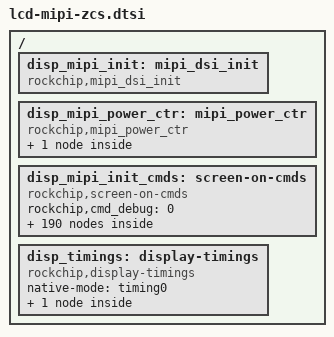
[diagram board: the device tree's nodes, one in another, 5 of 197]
/*
 * Copyright (C) 2014 ROCKCHIP, Inc.
 * Licensed under GPLv2 or later.
 * arch/arm/boot/dts/lcd-b080xan03.0-mipi.dtsi
 * author: chenyf@rock-chips.com
 * create date: 2014-09-11
 * lcd model: b080xan03.0
 * resolution: 768 X 1024
 * mipi channel: single
 */
//#include "include/dt-bindings/rkmipi/mipi_dsi.h"
#define HSDT                    0x00
#define LPDT                    0x01
/ {
		/* about mipi */
		disp_mipi_init: mipi_dsi_init{
					compatible = "rockchip,mipi_dsi_init";
					rockchip,screen_init	= <1>;
					rockchip,dsi_lane		= <4>;
					rockchip,dsi_hs_clk		= <480>;
					rockchip,mipi_dsi_num	= <1>;
		};
		disp_mipi_power_ctr: mipi_power_ctr {
					compatible = "rockchip,mipi_power_ctr";
					mipi_lcd_rst:mipi_lcd_rst{
							compatible = "rockchip,lcd_rst";
							rockchip,gpios = <&gpio0 GPIO_D0 GPIO_ACTIVE_HIGH>;
							rockchip,delay = <300>;
					};
					/*
					mipi_lcd_en:mipi_lcd_en {
							compatible = "rockchip,lcd_en";
							rockchip,gpios = <&gpio1 GPIO_B4 GPIO_ACTIVE_HIGH>;
							rockchip,delay = <100>;
					};*/
		};

disp_mipi_init_cmds: screen-on-cmds {
					compatible = "rockchip,screen-on-cmds";
					rockchip,cmd_debug = <0>;
					
					rockchip,on-cmds1 {
							compatible = "rockchip,on-cmds";
							rockchip,cmd_type = <LPDT>;
							rockchip,dsi_id = <0>;
							rockchip,cmd = <0x39 0xFF 0x98 0x81 0x03>;
							rockchip,cmd_delay = <0>;
					};
					
					rockchip,on-cmds2 {
							compatible = "rockchip,on-cmds";
							rockchip,cmd_type = <LPDT>;
							rockchip,dsi_id = <0>;
							rockchip,cmd = <0x15 0x01 0x00>;
							rockchip,cmd_delay = <0>;
					};
/*--------------------------------------------------------------------------------------------*/				
					rockchip,on-cmds3 {
							compatible = "rockchip,on-cmds";
							rockchip,cmd_type = <LPDT>;
							rockchip,dsi_id = <0>;
							rockchip,cmd = <0x15 0x02 0x00>;
							rockchip,cmd_delay = <0>;
					};
					rockchip,on-cmds4 {
							compatible = "rockchip,on-cmds";
							rockchip,cmd_type = <LPDT>;
							rockchip,dsi_id = <0>;
							rockchip,cmd = <0x15 0x03 0x53>;
							rockchip,cmd_delay = <0>;
					};
					rockchip,on-cmds5 {
							compatible = "rockchip,on-cmds";
							rockchip,cmd_type = <LPDT>;
							rockchip,dsi_id = <0>;
							rockchip,cmd = <0x15 0x04 0x14>;
							rockchip,cmd_delay = <0>;
					};
					rockchip,on-cmds6 {
							compatible = "rockchip,on-cmds";
							rockchip,cmd_type = <LPDT>;
							rockchip,dsi_id = <0>;
							rockchip,cmd = <0x15 0x05 0x00>;
							rockchip,cmd_delay = <0>;
					};
					rockchip,on-cmds7 {
							compatible = "rockchip,on-cmds";
							rockchip,cmd_type = <LPDT>;
							rockchip,dsi_id = <0>;
							rockchip,cmd = <0x15 0x06 0x06>;
							rockchip,cmd_delay = <0>;
					};
					rockchip,on-cmds8 {
							compatible = "rockchip,on-cmds";
							rockchip,cmd_type = <LPDT>;
							rockchip,dsi_id = <0>;
							rockchip,cmd =<0x15 0x07 0x01>;
							rockchip,cmd_delay = <0>;
					};					
					rockchip,on-cmds9 {
							compatible = "rockchip,on-cmds";
							rockchip,cmd_type = <LPDT>;
							rockchip,dsi_id = <0>;
							rockchip,cmd = <0x15 0x08 0x00>;
							rockchip,cmd_delay = <0>;
					};
					rockchip,on-cmds10 {
							compatible = "rockchip,on-cmds";
							rockchip,cmd_type = <LPDT>;
							rockchip,dsi_id = <0>;
							rockchip,cmd = <0x15 0x09 0x01>;
							rockchip,cmd_delay = <0>;
					};				
					rockchip,on-cmds11 {
							compatible = "rockchip,on-cmds";
							rockchip,cmd_type = <LPDT>;
							rockchip,dsi_id = <0>;
							rockchip,cmd = <0x15 0x0a 0x2f>;
							rockchip,cmd_delay = <0>;
					};		
					
					rockchip,on-cmds12 {
							compatible = "rockchip,on-cmds";
							rockchip,cmd_type = <LPDT>;
							rockchip,dsi_id = <0>;
							rockchip,cmd = <0x15 0x0b 0x01>;
							rockchip,cmd_delay = <0>;
					};

					rockchip,on-cmds13 {
							compatible = "rockchip,on-cmds";
							rockchip,cmd_type = <LPDT>;
							rockchip,dsi_id = <0>;
							rockchip,cmd = <0x15 0x0c 0x00>;
							rockchip,cmd_delay = <0>;
					};

					rockchip,on-cmds14 {
							compatible = "rockchip,on-cmds";
							rockchip,cmd_type = <LPDT>;
							rockchip,dsi_id = <0>;
							rockchip,cmd = <0x15 0x0d 0x00>;
							rockchip,cmd_delay = <0>;
					};
				

					rockchip,on-cmds15 {
							compatible = "rockchip,on-cmds";
							rockchip,cmd_type = <LPDT>;
							rockchip,dsi_id = <0>;
							rockchip,cmd = <0x15 0x0e 0x00>;
							rockchip,cmd_delay = <0>;
					};

					rockchip,on-cmds16 {
							compatible = "rockchip,on-cmds";
							rockchip,cmd_type = <LPDT>;
							rockchip,dsi_id = <0>;
							rockchip,cmd = <0x15 0x0f 0x2f>;
							rockchip,cmd_delay = <0>;
					};
			
					rockchip,on-cmds17 {
							compatible = "rockchip,on-cmds";
							rockchip,cmd_type = <LPDT>;
							rockchip,dsi_id = <0>;
							rockchip,cmd = <0x15 0x10 0x2f>;
							rockchip,cmd_delay = <0>;
					};

					rockchip,on-cmds18 {
							compatible = "rockchip,on-cmds";
							rockchip,cmd_type = <LPDT>;
							rockchip,dsi_id = <0>;
							rockchip,cmd = <0x15 0x11 0x00>;
							rockchip,cmd_delay = <0>;
					};rockchip,on-cmds19 {
							compatible = "rockchip,on-cmds";
							rockchip,cmd_type = <LPDT>;
							rockchip,dsi_id = <0>;
							rockchip,cmd = <0x15 0x12 0x00>;
							rockchip,cmd_delay = <0>;
					};rockchip,on-cmds20 {
							compatible = "rockchip,on-cmds";
							rockchip,cmd_type = <LPDT>;
							rockchip,dsi_id = <0>;
							rockchip,cmd = <0x15 0x13 0x00>;
							rockchip,cmd_delay = <0>;
					};rockchip,on-cmds21 {
							compatible = "rockchip,on-cmds";
							rockchip,cmd_type = <LPDT>;
							rockchip,dsi_id = <0>;
							rockchip,cmd = <0x15 0x14 0x00>;
							rockchip,cmd_delay = <0>;
					};rockchip,on-cmds22 {
							compatible = "rockchip,on-cmds";
							rockchip,cmd_type = <LPDT>;
							rockchip,dsi_id = <0>;
							rockchip,cmd = <0x15 0x15 0x00>;
							rockchip,cmd_delay = <0>;
					};rockchip,on-cmds23 {
							compatible = "rockchip,on-cmds";
							rockchip,cmd_type = <LPDT>;
							rockchip,dsi_id = <0>;
							rockchip,cmd = <0x15 0x16 0x00>;
							rockchip,cmd_delay = <0>;
					};rockchip,on-cmds24 {
							compatible = "rockchip,on-cmds";
							rockchip,cmd_type = <LPDT>;
							rockchip,dsi_id = <0>;
							rockchip,cmd = <0x15 0x17 0x00>;
							rockchip,cmd_delay = <0>;
					};rockchip,on-cmds25 {
							compatible = "rockchip,on-cmds";
							rockchip,cmd_type = <LPDT>;
							rockchip,dsi_id = <0>;
							rockchip,cmd = <0x15 0x18 0x00>;
							rockchip,cmd_delay = <0>;
					};rockchip,on-cmds26 {
							compatible = "rockchip,on-cmds";
							rockchip,cmd_type = <LPDT>;
							rockchip,dsi_id = <0>;
							rockchip,cmd = <0x15 0x19 0x00>;
							rockchip,cmd_delay = <0>;
					};rockchip,on-cmds27 {
							compatible = "rockchip,on-cmds";
							rockchip,cmd_type = <LPDT>;
							rockchip,dsi_id = <0>;
							rockchip,cmd = <0x15 0x1a 0x00>;
							rockchip,cmd_delay = <0>;
					};
					rockchip,on-cmds28 {
							compatible = "rockchip,on-cmds";
							rockchip,cmd_type = <LPDT>;
							rockchip,dsi_id = <0>;
							rockchip,cmd = <0x15 0x1b 0x00>;
							rockchip,cmd_delay = <0>;
					};
					rockchip,on-cmds29 {
							compatible = "rockchip,on-cmds";
							rockchip,cmd_type = <LPDT>;
							rockchip,dsi_id = <0>;
							rockchip,cmd = <0x15 0x1c 0x00>;
							rockchip,cmd_delay = <0>;
					};

					rockchip,on-cmds30 {
							compatible = "rockchip,on-cmds";
							rockchip,cmd_type = <LPDT>;
							rockchip,dsi_id = <0>;
							rockchip,cmd = <0x15 0x1d 0x00>;
							rockchip,cmd_delay = <0>;
					};
					rockchip,on-cmds31 {
							compatible = "rockchip,on-cmds";
							rockchip,cmd_type = <LPDT>;
							rockchip,dsi_id = <0>;
							rockchip,cmd = <0x15 0x1e 0x40>;
							rockchip,cmd_delay = <0>;
					};
					rockchip,on-cmds32 {
							compatible = "rockchip,on-cmds";
							rockchip,cmd_type = <LPDT>;
							rockchip,dsi_id = <0>;
							rockchip,cmd = <0x15 0x1f 0x40>;
							rockchip,cmd_delay = <0>;
					};
					rockchip,on-cmds33 {
							compatible = "rockchip,on-cmds";
							rockchip,cmd_type = <LPDT>;
							rockchip,dsi_id = <0>;
							rockchip,cmd = <0x15 0x20 0x02>;
							rockchip,cmd_delay = <0>;
					};
					rockchip,on-cmds34 {
							compatible = "rockchip,on-cmds";
							rockchip,cmd_type = <LPDT>;
							rockchip,dsi_id = <0>;
							rockchip,cmd = <0x15 0x21 0x05>;
							rockchip,cmd_delay = <0>;
					};
					rockchip,on-cmds35 {
							compatible = "rockchip,on-cmds";
							rockchip,cmd_type = <LPDT>;
							rockchip,dsi_id = <0>;
							rockchip,cmd = <0x15 0x22 0x02>;
							rockchip,cmd_delay = <0>;
					};
					rockchip,on-cmds36 {
							compatible = "rockchip,on-cmds";
							rockchip,cmd_type = <LPDT>;
							rockchip,dsi_id = <0>;
							rockchip,cmd = <0x15 0x23 0x00>;
							rockchip,cmd_delay = <0>;
					};
					rockchip,on-cmds37 {
							compatible = "rockchip,on-cmds";
							rockchip,cmd_type = <LPDT>;
							rockchip,dsi_id = <0>;
							rockchip,cmd = <0x15 0x24 0x87>;
							rockchip,cmd_delay = <0>;
					};
					rockchip,on-cmds38 {
							compatible = "rockchip,on-cmds";
							rockchip,cmd_type = <LPDT>;
							rockchip,dsi_id = <0>;
							rockchip,cmd = <0x15 0x25 0x87>;
							rockchip,cmd_delay = <0>;
					};
					rockchip,on-cmds39 {
							compatible = "rockchip,on-cmds";
							rockchip,cmd_type = <LPDT>;
							rockchip,dsi_id = <0>;
							rockchip,cmd = <0x15 0x26 0x00>;
							rockchip,cmd_delay = <0>;
					};
					rockchip,on-cmds40 {
							compatible = "rockchip,on-cmds";
							rockchip,cmd_type = <LPDT>;
							rockchip,dsi_id = <0>;
							rockchip,cmd = <0x15 0x27 0x00>;
							rockchip,cmd_delay = <0>;
					};
					rockchip,on-cmds41 {
							compatible = "rockchip,on-cmds";
							rockchip,cmd_type = <LPDT>;
							rockchip,dsi_id = <0>;
							rockchip,cmd = <0x15 0x28 0x3B>;
							rockchip,cmd_delay = <0>;
					};
					
					rockchip,on-cmds42 {
							compatible = "rockchip,on-cmds";
							rockchip,cmd_type = <LPDT>;
							rockchip,dsi_id = <0>;
							rockchip,cmd = <0x15 0x29 0x03>;
							rockchip,cmd_delay = <0>;
					};
					rockchip,on-cmds43 {
							compatible = "rockchip,on-cmds";
							rockchip,cmd_type = <LPDT>;
							rockchip,dsi_id = <0>;
							rockchip,cmd = <0x15 0x2a 0x00>;
							rockchip,cmd_delay = <0>;
					};
			
					rockchip,on-cmds44 {
							compatible = "rockchip,on-cmds";
							rockchip,cmd_type = <LPDT>;
							rockchip,dsi_id = <0>;
							rockchip,cmd = <0x15 0x2b 0x00>;
							rockchip,cmd_delay = <0>;
					};
					
					rockchip,on-cmds45 {
							compatible = "rockchip,on-cmds";
							rockchip,cmd_type = <LPDT>;
							rockchip,dsi_id = <0>;
							rockchip,cmd = <0x15 0x2c 0x00	>;
							rockchip,cmd_delay = <0>;
					};
					
					
					rockchip,on-cmds46 {
							compatible = "rockchip,on-cmds";
							rockchip,cmd_type = <LPDT>;
							rockchip,dsi_id = <0>;
							rockchip,cmd = <0x15 0x2d 0x00>;
							rockchip,cmd_delay = <0>;
					};

					rockchip,on-cmds47 {
							compatible = "rockchip,on-cmds";
							rockchip,cmd_type = <LPDT>;
							rockchip,dsi_id = <0>;
							rockchip,cmd = <0x15 0x2e 0x00>;
							rockchip,cmd_delay = <0>;
					};

					rockchip,on-cmds48 {
							compatible = "rockchip,on-cmds";
							rockchip,cmd_type = <LPDT>;
							rockchip,dsi_id = <0>;
							rockchip,cmd = <0x15 0x2f 0x00>;
							rockchip,cmd_delay = <0>;
							
					};
					rockchip,on-cmds49 {
							compatible = "rockchip,on-cmds";
							rockchip,cmd_type = <LPDT>;
							rockchip,dsi_id = <0>;
							rockchip,cmd = <0x15 0x30 0x00>;
							rockchip,cmd_delay = <0>;
					};
					rockchip,on-cmds50 {
							compatible = "rockchip,on-cmds";
							rockchip,cmd_type = <LPDT>;
							rockchip,dsi_id = <0>;
							rockchip,cmd = <0x15 0x31 0x00>;
							rockchip,cmd_delay = <0>;
					};
					rockchip,on-cmds51 {
							compatible = "rockchip,on-cmds";
							rockchip,cmd_type = <LPDT>;
							rockchip,dsi_id = <0>;
							rockchip,cmd = <0x15 0x32 0x00>;
							rockchip,cmd_delay = <0>;
					};
					rockchip,on-cmds52 {
							compatible = "rockchip,on-cmds";
							rockchip,cmd_type = <LPDT>;
							rockchip,dsi_id = <0>;
							rockchip,cmd = <0x15 0x33 0x00>;
							rockchip,cmd_delay = <0>;
					};
					rockchip,on-cmds53 {
							compatible = "rockchip,on-cmds";
							rockchip,cmd_type = <LPDT>;
							rockchip,dsi_id = <0>;
							rockchip,cmd = <0x15 0x34 0x04>;
							rockchip,cmd_delay = <0>;
					};
					rockchip,on-cmds54 {
							compatible = "rockchip,on-cmds";
							rockchip,cmd_type = <LPDT>;
							rockchip,dsi_id = <0>;
							rockchip,cmd = <0x15 0x35 0x00>;
							rockchip,cmd_delay = <0>;
					};
					rockchip,on-cmds55 {
							compatible = "rockchip,on-cmds";
							rockchip,cmd_type = <LPDT>;
							rockchip,dsi_id = <0>;
							rockchip,cmd = <0x15 0x36 0x00>;
							rockchip,cmd_delay = <0>;
					};
					rockchip,on-cmds56 {
							compatible = "rockchip,on-cmds";
							rockchip,cmd_type = <LPDT>;
							rockchip,dsi_id = <0>;
							rockchip,cmd = <0x15 0x37 0x00>;
							rockchip,cmd_delay = <0>;
					};
					rockchip,on-cmds57 {
							compatible = "rockchip,on-cmds";
							rockchip,cmd_type = <LPDT>;
							rockchip,dsi_id = <0>;
							rockchip,cmd = <0x15 0x38 0x01>;
							rockchip,cmd_delay = <0>;
					};
					rockchip,on-cmds58 {
							compatible = "rockchip,on-cmds";
							rockchip,cmd_type = <LPDT>;
							rockchip,dsi_id = <0>;
							rockchip,cmd = <0x15 0x39 0x01>;
							rockchip,cmd_delay = <0>;
					};
					rockchip,on-cmds59 {
							compatible = "rockchip,on-cmds";
							rockchip,cmd_type = <LPDT>;
							rockchip,dsi_id = <0>;
							rockchip,cmd = <0x15 0x3a 0x40>;
							rockchip,cmd_delay = <0>;
					};
					rockchip,on-cmds60 {
							compatible = "rockchip,on-cmds";
							rockchip,cmd_type = <LPDT>;
							rockchip,dsi_id = <0>;
							rockchip,cmd = <0x15 0x3b 0x40>;
							rockchip,cmd_delay = <0>;
					};
					rockchip,on-cmds61 {
							compatible = "rockchip,on-cmds";
							rockchip,cmd_type = <LPDT>;
							rockchip,dsi_id = <0>;
							rockchip,cmd = <0x15 0x3c 0x00>;
							rockchip,cmd_delay = <0>;
					};
					rockchip,on-cmds62 {
							compatible = "rockchip,on-cmds";
							rockchip,cmd_type = <LPDT>;
							rockchip,dsi_id = <0>;
							rockchip,cmd = <0x15 0x3d 0x00>;
							rockchip,cmd_delay = <0>;
					};
					rockchip,on-cmds63 {
							compatible = "rockchip,on-cmds";
							rockchip,cmd_type = <LPDT>;
							rockchip,dsi_id = <0>;
							rockchip,cmd = <0x15 0x3e 0x00>;
							rockchip,cmd_delay = <0>;
					};
					rockchip,on-cmds64 {
							compatible = "rockchip,on-cmds";
							rockchip,cmd_type = <LPDT>;
							rockchip,dsi_id = <0>;
							rockchip,cmd = <0x15 0x3f 0x00>;
							rockchip,cmd_delay = <0>;
					};
					rockchip,on-cmds65 {
							compatible = "rockchip,on-cmds";
							rockchip,cmd_type = <LPDT>;
							rockchip,dsi_id = <0>;
							rockchip,cmd = <0x15 0x40 0x00>;
							rockchip,cmd_delay = <0>;
					};
					rockchip,on-cmds66 {
							compatible = "rockchip,on-cmds";
							rockchip,cmd_type = <LPDT>;
							rockchip,dsi_id = <0>;
							rockchip,cmd = <0x15 0x41 0x88>;
							rockchip,cmd_delay = <0>;
					};
					rockchip,on-cmds67 {
							compatible = "rockchip,on-cmds";
							rockchip,cmd_type = <LPDT>;
							rockchip,dsi_id = <0>;
							rockchip,cmd = <0x15 0x42 0x00>;
							rockchip,cmd_delay = <0>;
					};
					rockchip,on-cmds68 {
							compatible = "rockchip,on-cmds";
							rockchip,cmd_type = <LPDT>;
							rockchip,dsi_id = <0>;
							rockchip,cmd = <0x15 0x43 0x00>;
							rockchip,cmd_delay = <0>;
					};
					rockchip,on-cmds69 {
							compatible = "rockchip,on-cmds";
							rockchip,cmd_type = <LPDT>;
							rockchip,dsi_id = <0>;
							rockchip,cmd = <0x15 0x44 0x00>;
							rockchip,cmd_delay = <0>;
					};
					rockchip,on-cmds70 {
							compatible = "rockchip,on-cmds";
							rockchip,cmd_type = <LPDT>;
							rockchip,dsi_id = <0>;
							rockchip,cmd = <0x15 0x50 0x01>;
							rockchip,cmd_delay = <0>;
					};
					rockchip,on-cmds71 {
							compatible = "rockchip,on-cmds";
							rockchip,cmd_type = <LPDT>;
							rockchip,dsi_id = <0>;
							rockchip,cmd = <0x15 0x51 0x23>;
							rockchip,cmd_delay = <0>;
					};
					rockchip,on-cmds72 {
							compatible = "rockchip,on-cmds";
							rockchip,cmd_type = <LPDT>;
							rockchip,dsi_id = <0>;
							rockchip,cmd = <0x15 0x52 0x45>;
							rockchip,cmd_delay = <0>;
					};
					rockchip,on-cmds73 {
							compatible = "rockchip,on-cmds";
							rockchip,cmd_type = <LPDT>;
							rockchip,dsi_id = <0>;
							rockchip,cmd = <0x15 0x53 0x67>;
							rockchip,cmd_delay = <0>;
					};
					rockchip,on-cmds74 {
							compatible = "rockchip,on-cmds";
							rockchip,cmd_type = <LPDT>;
							rockchip,dsi_id = <0>;
							rockchip,cmd = <0x15 0x54 0x89>;
							rockchip,cmd_delay = <0>;
					};
					rockchip,on-cmds75 {
							compatible = "rockchip,on-cmds";
							rockchip,cmd_type = <LPDT>;
							rockchip,dsi_id = <0>;
							rockchip,cmd = <0x15 0x55 0xab>;
							rockchip,cmd_delay = <0>;
					};
					rockchip,on-cmds76 {
							compatible = "rockchip,on-cmds";
							rockchip,cmd_type = <LPDT>;
							rockchip,dsi_id = <0>;
							rockchip,cmd = <0x15 0x56 0x01>;
							rockchip,cmd_delay = <0>;
					};
					rockchip,on-cmds77 {
							compatible = "rockchip,on-cmds";
							rockchip,cmd_type = <LPDT>;
							rockchip,dsi_id = <0>;
							rockchip,cmd = <0x15 0x57 0x23>;
							rockchip,cmd_delay = <0>;
					};
					rockchip,on-cmds78 {
							compatible = "rockchip,on-cmds";
							rockchip,cmd_type = <LPDT>;
							rockchip,dsi_id = <0>;
							rockchip,cmd = <0x15 0x58 0x45>;
							rockchip,cmd_delay = <0>;
					};
					rockchip,on-cmds79 {
							compatible = "rockchip,on-cmds";
							rockchip,cmd_type = <LPDT>;
							rockchip,dsi_id = <0>;
							rockchip,cmd = <0x15 0x59 0x67>;
							rockchip,cmd_delay = <0>;
					};
					rockchip,on-cmds80 {
							compatible = "rockchip,on-cmds";
							rockchip,cmd_type = <LPDT>;
							rockchip,dsi_id = <0>;
							rockchip,cmd = <0x15 0x5a 0x89>;
							rockchip,cmd_delay = <0>;
					};
					rockchip,on-cmds81 {
							compatible = "rockchip,on-cmds";
							rockchip,cmd_type = <LPDT>;
							rockchip,dsi_id = <0>;
							rockchip,cmd = <0x15 0x5b 0xab>;
							rockchip,cmd_delay = <0>;
					};
					rockchip,on-cmds82 {
							compatible = "rockchip,on-cmds";
							rockchip,cmd_type = <LPDT>;
							rockchip,dsi_id = <0>;
							rockchip,cmd = <0x15 0x5c 0xcd>;
							rockchip,cmd_delay = <0>;
					};
					rockchip,on-cmds83 {
							compatible = "rockchip,on-cmds";
							rockchip,cmd_type = <LPDT>;
							rockchip,dsi_id = <0>;
							rockchip,cmd = <0x15 0x5d 0xef>;
							rockchip,cmd_delay = <0>;
					};
					rockchip,on-cmds84 {
							compatible = "rockchip,on-cmds";
							rockchip,cmd_type = <LPDT>;
							rockchip,dsi_id = <0>;
							rockchip,cmd = <0x15 0x5e 0x11>;
							rockchip,cmd_delay = <0>;
					};
					rockchip,on-cmds85 {
							compatible = "rockchip,on-cmds";
							rockchip,cmd_type = <LPDT>;
							rockchip,dsi_id = <0>;
							rockchip,cmd = <0x15 0x5f 0x06>;
							rockchip,cmd_delay = <0>;
					};
					rockchip,on-cmds86 {
							compatible = "rockchip,on-cmds";
							rockchip,cmd_type = <LPDT>;
							rockchip,dsi_id = <0>;
							rockchip,cmd = <0x15 0x60 0x0C>;
							rockchip,cmd_delay = <0>;
					};
					rockchip,on-cmds87 {
							compatible = "rockchip,on-cmds";
							rockchip,cmd_type = <LPDT>;
							rockchip,dsi_id = <0>;
							rockchip,cmd = <0x15 0x61 0x0D>;
							rockchip,cmd_delay = <0>;
					};
					rockchip,on-cmds88 {
							compatible = "rockchip,on-cmds";
							rockchip,cmd_type = <LPDT>;
							rockchip,dsi_id = <0>;
							rockchip,cmd = <0x15 0x62 0x0E>;
							rockchip,cmd_delay = <0>;
					};
					rockchip,on-cmds89 {
							compatible = "rockchip,on-cmds";
							rockchip,cmd_type = <LPDT>;
							rockchip,dsi_id = <0>;
							rockchip,cmd = <0x15 0x63 0x0F>;
							rockchip,cmd_delay = <0>;
					};
					rockchip,on-cmds90 {
							compatible = "rockchip,on-cmds";
							rockchip,cmd_type = <LPDT>;
							rockchip,dsi_id = <0>;
							rockchip,cmd = <0x15 0x64 0x02>;
							rockchip,cmd_delay = <0>;
					};
					rockchip,on-cmds91 {
							compatible = "rockchip,on-cmds";
							rockchip,cmd_type = <LPDT>;
							rockchip,dsi_id = <0>;
							rockchip,cmd = <0x15 0x65 0x02>;
							rockchip,cmd_delay = <0>;
					};
					rockchip,on-cmds92 {
							compatible = "rockchip,on-cmds";
							rockchip,cmd_type = <LPDT>;
							rockchip,dsi_id = <0>;
							rockchip,cmd = <0x15 0x66 0x02>;
							rockchip,cmd_delay = <0>;
					};
					rockchip,on-cmds93 {
							compatible = "rockchip,on-cmds";
							rockchip,cmd_type = <LPDT>;
							rockchip,dsi_id = <0>;
							rockchip,cmd = <0x15 0x67 0x02>;
							rockchip,cmd_delay = <0>;
					};
					rockchip,on-cmds94 {
							compatible = "rockchip,on-cmds";
							rockchip,cmd_type = <LPDT>;
							rockchip,dsi_id = <0>;
							rockchip,cmd = <0x15 0x68 0x02>;
							rockchip,cmd_delay = <0>;
					};
					rockchip,on-cmds95 {
							compatible = "rockchip,on-cmds";
							rockchip,cmd_type = <LPDT>;
							rockchip,dsi_id = <0>;
							rockchip,cmd = <0x15 0x69 0x02>;
							rockchip,cmd_delay = <0>;
					};
					rockchip,on-cmds96 {
							compatible = "rockchip,on-cmds";
							rockchip,cmd_type = <LPDT>;
							rockchip,dsi_id = <0>;
							rockchip,cmd = <0x15 0x6a 0x02>;
							rockchip,cmd_delay = <0>;
					};
					rockchip,on-cmds97 {
							compatible = "rockchip,on-cmds";
							rockchip,cmd_type = <LPDT>;
							rockchip,dsi_id = <0>;
							rockchip,cmd = <0x15 0x6b 0x02>;
							rockchip,cmd_delay = <0>;
					};
					rockchip,on-cmds98 {
							compatible = "rockchip,on-cmds";
							rockchip,cmd_type = <LPDT>;
							rockchip,dsi_id = <0>;
							rockchip,cmd = <0x15 0x6c 0x02>;
							rockchip,cmd_delay = <0>;
					};
					rockchip,on-cmds99 {
							compatible = "rockchip,on-cmds";
							rockchip,cmd_type = <LPDT>;
							rockchip,dsi_id = <0>;
							rockchip,cmd = <0x15 0x6d 0x02>;
							rockchip,cmd_delay = <0>;
					};
					rockchip,on-cmds100 {
							compatible = "rockchip,on-cmds";
							rockchip,cmd_type = <LPDT>;
							rockchip,dsi_id = <0>;
							rockchip,cmd = <0x15 0x6e 0x05>;
							rockchip,cmd_delay = <0>;
					};
					rockchip,on-cmds101 {
							compatible = "rockchip,on-cmds";
							rockchip,cmd_type = <LPDT>;
							rockchip,dsi_id = <0>;
							rockchip,cmd = <0x15 0x6f 0x05>;
							rockchip,cmd_delay = <0>;
					};
					rockchip,on-cmds102 {
							compatible = "rockchip,on-cmds";
							rockchip,cmd_type = <LPDT>;
							rockchip,dsi_id = <0>;
							rockchip,cmd = <0x15 0x70 0x05>;
							rockchip,cmd_delay = <0>;
					};
					rockchip,on-cmds103 {
							compatible = "rockchip,on-cmds";
							rockchip,cmd_type = <LPDT>;
							rockchip,dsi_id = <0>;
							rockchip,cmd = <0x15 0x71 0x02>;
							rockchip,cmd_delay = <0>;
					};
					rockchip,on-cmds104 {
							compatible = "rockchip,on-cmds";
							rockchip,cmd_type = <LPDT>;
							rockchip,dsi_id = <0>;
							rockchip,cmd = <0x15 0x72 0x01>;
							rockchip,cmd_delay = <0>;
					};
					rockchip,on-cmds105 {
							compatible = "rockchip,on-cmds";
							rockchip,cmd_type = <LPDT>;
							rockchip,dsi_id = <0>;
							rockchip,cmd = <0x15 0x73 0x00>;
							rockchip,cmd_delay = <0>;
					};
					rockchip,on-cmds106 {
							compatible = "rockchip,on-cmds";
							rockchip,cmd_type = <LPDT>;
							rockchip,dsi_id = <0>;
							rockchip,cmd = <0x15 0x74 0x08>;
							rockchip,cmd_delay = <0>;
					};
					rockchip,on-cmds107 {
							compatible = "rockchip,on-cmds";
							rockchip,cmd_type = <LPDT>;
							rockchip,dsi_id = <0>;
							rockchip,cmd = <0x15 0x75 0x08>;
							rockchip,cmd_delay = <0>;
					};
					rockchip,on-cmds108 {
							compatible = "rockchip,on-cmds";
							rockchip,cmd_type = <LPDT>;
							rockchip,dsi_id = <0>;
							rockchip,cmd = <0x15 0x76 0x0C>;
							rockchip,cmd_delay = <0>;
					};
					rockchip,on-cmds109 {
							compatible = "rockchip,on-cmds";
							rockchip,cmd_type = <LPDT>;
							rockchip,dsi_id = <0>;
							rockchip,cmd = <0x15 0x77 0x0D>;
							rockchip,cmd_delay = <0>;
					};
					rockchip,on-cmds110 {
							compatible = "rockchip,on-cmds";
							rockchip,cmd_type = <LPDT>;
							rockchip,dsi_id = <0>;
							rockchip,cmd = <0x15 0x78 0x0E>;
							rockchip,cmd_delay = <0>;
					};
					rockchip,on-cmds111 {
							compatible = "rockchip,on-cmds";
							rockchip,cmd_type = <LPDT>;
							rockchip,dsi_id = <0>;
							rockchip,cmd = <0x15 0x79 0x0F>;
							rockchip,cmd_delay = <0>;
					};
					rockchip,on-cmds112 {
							compatible = "rockchip,on-cmds";
							rockchip,cmd_type = <LPDT>;
							rockchip,dsi_id = <0>;
							rockchip,cmd = <0x15 0x7a 0x02>;
							rockchip,cmd_delay = <0>;
					};
rockchip,on-cmds113 {
							compatible = "rockchip,on-cmds";
							rockchip,cmd_type = <LPDT>;
							rockchip,dsi_id = <0>;
							rockchip,cmd = <0x15 0x7b 0x02>;
							rockchip,cmd_delay = <0>;
					};
rockchip,on-cmds114 {
							compatible = "rockchip,on-cmds";
							rockchip,cmd_type = <LPDT>;
							rockchip,dsi_id = <0>;
							rockchip,cmd = <0x15 0x7c 0x02>;
							rockchip,cmd_delay = <0>;
					};
rockchip,on-cmds115 {
							compatible = "rockchip,on-cmds";
							rockchip,cmd_type = <LPDT>;
							rockchip,dsi_id = <0>;
							rockchip,cmd = <0x15 0x7d 0x02>;
							rockchip,cmd_delay = <0>;
					};
rockchip,on-cmds116 {
							compatible = "rockchip,on-cmds";
							rockchip,cmd_type = <LPDT>;
							rockchip,dsi_id = <0>;
							rockchip,cmd = <0x15 0x7e 0x02>;
							rockchip,cmd_delay = <0>;
					};
rockchip,on-cmds117 {
							compatible = "rockchip,on-cmds";
							rockchip,cmd_type = <LPDT>;
							rockchip,dsi_id = <0>;
							rockchip,cmd = <0x15 0x7f 0x02>;
							rockchip,cmd_delay = <0>;
					};
rockchip,on-cmds118 {
							compatible = "rockchip,on-cmds";
							rockchip,cmd_type = <LPDT>;
							rockchip,dsi_id = <0>;
							rockchip,cmd = <0x15 0x80 0x02>;
							rockchip,cmd_delay = <0>;
					};
rockchip,on-cmds119 {
							compatible = "rockchip,on-cmds";
							rockchip,cmd_type = <LPDT>;
							rockchip,dsi_id = <0>;
							rockchip,cmd = <0x15 0x81 0x02>;
							rockchip,cmd_delay = <0>;
					};
rockchip,on-cmds120 {
							compatible = "rockchip,on-cmds";
							rockchip,cmd_type = <LPDT>;
							rockchip,dsi_id = <0>;
							rockchip,cmd = <0x15 0x82 0x02>;
							rockchip,cmd_delay = <0>;
					};
rockchip,on-cmds121 {
							compatible = "rockchip,on-cmds";
							rockchip,cmd_type = <LPDT>;
							rockchip,dsi_id = <0>;
							rockchip,cmd = <0x15 0x83 0x02>;
							rockchip,cmd_delay = <0>;
					};
rockchip,on-cmds122 {
							compatible = "rockchip,on-cmds";
							rockchip,cmd_type = <LPDT>;
							rockchip,dsi_id = <0>;
							rockchip,cmd = <0x15 0x84 0x05>;
							rockchip,cmd_delay = <0>;
					};
rockchip,on-cmds123 {
							compatible = "rockchip,on-cmds";
							rockchip,cmd_type = <LPDT>;
							rockchip,dsi_id = <0>;
							rockchip,cmd = <0x15 0x85 0x05>;
							rockchip,cmd_delay = <0>;
					};
rockchip,on-cmds124 {
							compatible = "rockchip,on-cmds";
							rockchip,cmd_type = <LPDT>;
							rockchip,dsi_id = <0>;
							rockchip,cmd = <0x15 0x86 0x05>;
							rockchip,cmd_delay = <0>;
					};
rockchip,on-cmds125 {
							compatible = "rockchip,on-cmds";
							rockchip,cmd_type = <LPDT>;
							rockchip,dsi_id = <0>;
							rockchip,cmd = <0x15 0x87 0x02>;
							rockchip,cmd_delay = <0>;
					};
rockchip,on-cmds126 {
							compatible = "rockchip,on-cmds";
							rockchip,cmd_type = <LPDT>;
							rockchip,dsi_id = <0>;
							rockchip,cmd = <0x15 0x88 0x01>;
							rockchip,cmd_delay = <0>;
					};
rockchip,on-cmds127 {
							compatible = "rockchip,on-cmds";
							rockchip,cmd_type = <LPDT>;
							rockchip,dsi_id = <0>;
							rockchip,cmd = <0x15 0x89 0x00>;
							rockchip,cmd_delay = <0>;
					};
rockchip,on-cmds128 {
							compatible = "rockchip,on-cmds";
							rockchip,cmd_type = <LPDT>;
							rockchip,dsi_id = <0>;
							rockchip,cmd = <0x15 0x8A 0x06>;
							rockchip,cmd_delay = <0>;
					};
					
rockchip,on-cmds129 {
							compatible = "rockchip,on-cmds";
							rockchip,cmd_type = <LPDT>;
							rockchip,dsi_id = <0>;
							rockchip,cmd = <0x39 0xFF 0x98 0x81 0x04>;//CMD PAGE4
							rockchip,cmd_delay = <0>;
					};
rockchip,on-cmds130 {
							compatible = "rockchip,on-cmds";
							rockchip,cmd_type = <LPDT>;
							rockchip,dsi_id = <0>;
							rockchip,cmd = <0x15 0x6C 0x15 >;
							rockchip,cmd_delay = <0>;
					};
rockchip,on-cmds131 {
							compatible = "rockchip,on-cmds";
							rockchip,cmd_type = <LPDT>;
							rockchip,dsi_id = <0>;
							rockchip,cmd = <0x15 0x6E 0x2b >;//hyl 0x1a
							rockchip,cmd_delay = <0>;
					};
rockchip,on-cmds132 {
							compatible = "rockchip,on-cmds";
							rockchip,cmd_type = <LPDT>;
							rockchip,dsi_id = <0>;
							rockchip,cmd = <0x15 0x6F 0x33 >;
							rockchip,cmd_delay = <0>;
					};
rockchip,on-cmds133 {
							compatible = "rockchip,on-cmds";
							rockchip,cmd_type = <LPDT>;
							rockchip,dsi_id = <0>;
							rockchip,cmd = <0x15 0x3A 0xa4>;//VGL clamp -9.6V
							rockchip,cmd_delay = <0>;
					};
rockchip,on-cmds134 {
							compatible = "rockchip,on-cmds";
							rockchip,cmd_type = <LPDT>;
							rockchip,dsi_id = <0>;
							rockchip,cmd = <0x15 0x8D 0x15>;//POWER SAVING
							rockchip,cmd_delay = <0>;
					};
rockchip,on-cmds135 {
							compatible = "rockchip,on-cmds";
							rockchip,cmd_type = <LPDT>;
							rockchip,dsi_id = <0>;
							rockchip,cmd = <0x15 0x87 0xBA>;
							rockchip,cmd_delay = <0>;
					};
rockchip,on-cmds136 {
							compatible = "rockchip,on-cmds";
							rockchip,cmd_type = <LPDT>;
							rockchip,dsi_id = <0>;
							rockchip,cmd = <0x15 0x26 0x76>;
							rockchip,cmd_delay = <0>;
					};
rockchip,on-cmds137 {
							compatible = "rockchip,on-cmds";
							rockchip,cmd_type = <LPDT>;
							rockchip,dsi_id = <0>;
							rockchip,cmd = <0x15 0xB2 0xD1>;
							rockchip,cmd_delay = <0>;
					};
rockchip,on-cmds138 {
							compatible = "rockchip,on-cmds";
							rockchip,cmd_type = <LPDT>;
							rockchip,dsi_id = <0>;
							rockchip,cmd = <0x39 0xFF 0x98 0x81 0x01>;
							rockchip,cmd_delay = <0>;
					};
rockchip,on-cmds139 {
							compatible = "rockchip,on-cmds";
							rockchip,cmd_type = <LPDT>;
							rockchip,dsi_id = <0>;
							rockchip,cmd = <0x15 0x22 0x0A>;
							rockchip,cmd_delay = <0>;
					};
rockchip,on-cmds140 {
							compatible = "rockchip,on-cmds";
							rockchip,cmd_type = <LPDT>;
							rockchip,dsi_id = <0>;
							rockchip,cmd = <0x15 0x53 0x95>;
							rockchip,cmd_delay = <0>;
					};
rockchip,on-cmds141 {
							compatible = "rockchip,on-cmds";
							rockchip,cmd_type = <LPDT>;
							rockchip,dsi_id = <0>;
							rockchip,cmd = <0x15 0x55 0xA5>;
							rockchip,cmd_delay = <0>;
					};
rockchip,on-cmds142 {
							compatible = "rockchip,on-cmds";
							rockchip,cmd_type = <LPDT>;
							rockchip,dsi_id = <0>;
							rockchip,cmd = <0x15 0x50 0xB9>;
							rockchip,cmd_delay = <0>;
					};
rockchip,on-cmds143 {
							compatible = "rockchip,on-cmds";
							rockchip,cmd_type = <LPDT>;
							rockchip,dsi_id = <0>;
							rockchip,cmd = <0x15 0x51 0xBA>;
							rockchip,cmd_delay = <0>;
					};
rockchip,on-cmds144 {
							compatible = "rockchip,on-cmds";
							rockchip,cmd_type = <LPDT>;
							rockchip,dsi_id = <0>;
							rockchip,cmd = <0x15 0x31 0x00>;
							rockchip,cmd_delay = <0>;
					};
rockchip,on-cmds145 {
							compatible = "rockchip,on-cmds";
							rockchip,cmd_type = <LPDT>;
							rockchip,dsi_id = <0>;
							rockchip,cmd = <0x15 0x60 0x14>;
							rockchip,cmd_delay = <0>;
					};
rockchip,on-cmds146 {
							compatible = "rockchip,on-cmds";
							rockchip,cmd_type = <LPDT>;
							rockchip,dsi_id = <0>;
							rockchip,cmd = <0x15 0x61 0x00>;
							rockchip,cmd_delay = <0>;
					};
rockchip,on-cmds147 {
							compatible = "rockchip,on-cmds";
							rockchip,cmd_type = <LPDT>;
							rockchip,dsi_id = <0>;
							rockchip,cmd = <0x15 0xA0 0x1d>;
							rockchip,cmd_delay = <0>;
					};
rockchip,on-cmds148 {
							compatible = "rockchip,on-cmds";
							rockchip,cmd_type = <LPDT>;
							rockchip,dsi_id = <0>;
							rockchip,cmd = <0x15 0xA1 0x2b>;
							rockchip,cmd_delay = <0>;
					};
rockchip,on-cmds149 {
							compatible = "rockchip,on-cmds";
							rockchip,cmd_type = <LPDT>;
							rockchip,dsi_id = <0>;
							rockchip,cmd = <0x15 0xA2 0x36>;
							rockchip,cmd_delay = <0>;
					};
rockchip,on-cmds150 {
							compatible = "rockchip,on-cmds";
							rockchip,cmd_type = <LPDT>;
							rockchip,dsi_id = <0>;
							rockchip,cmd = <0x15 0xA3 0x0d>;
							rockchip,cmd_delay = <0>;
					};
rockchip,on-cmds151 {
							compatible = "rockchip,on-cmds";
							rockchip,cmd_type = <LPDT>;
							rockchip,dsi_id = <0>;
							rockchip,cmd = <0x15 0xA4 0x0d>;
							rockchip,cmd_delay = <0>;
					};
rockchip,on-cmds152 {
							compatible = "rockchip,on-cmds";
							rockchip,cmd_type = <LPDT>;
							rockchip,dsi_id = <0>;
							rockchip,cmd = <0x15 0xA5 0x1e>;
							rockchip,cmd_delay = <0>;
					};
rockchip,on-cmds153 {
							compatible = "rockchip,on-cmds";
							rockchip,cmd_type = <LPDT>;
							rockchip,dsi_id = <0>;
							rockchip,cmd = <0x15 0xA6 0x15>;
							rockchip,cmd_delay = <0>;
					};
rockchip,on-cmds154 {
							compatible = "rockchip,on-cmds";
							rockchip,cmd_type = <LPDT>;
							rockchip,dsi_id = <0>;
							rockchip,cmd = <0x15 0xA7 0x1b>;
							rockchip,cmd_delay = <0>;
					};
rockchip,on-cmds155 {
							compatible = "rockchip,on-cmds";
							rockchip,cmd_type = <LPDT>;
							rockchip,dsi_id = <0>;
							rockchip,cmd = <0x15 0xA8 0x91>;
							rockchip,cmd_delay = <0>;
					};
rockchip,on-cmds156 {
							compatible = "rockchip,on-cmds";
							rockchip,cmd_type = <LPDT>;
							rockchip,dsi_id = <0>;
							rockchip,cmd = <0x15 0xA9 0x1A>;
							rockchip,cmd_delay = <0>;
					};
rockchip,on-cmds157 {
							compatible = "rockchip,on-cmds";
							rockchip,cmd_type = <LPDT>;
							rockchip,dsi_id = <0>;
							rockchip,cmd = <0x15 0xAA 0x25>;
							rockchip,cmd_delay = <0>;
					};
rockchip,on-cmds158 {
							compatible = "rockchip,on-cmds";
							rockchip,cmd_type = <LPDT>;
							rockchip,dsi_id = <0>;
							rockchip,cmd = <0x15 0xAB 0x8c>;
							rockchip,cmd_delay = <0>;
					};
rockchip,on-cmds159 {
							compatible = "rockchip,on-cmds";
							rockchip,cmd_type = <LPDT>;
							rockchip,dsi_id = <0>;
							rockchip,cmd = <0x15 0xAC 0x1b>;
							rockchip,cmd_delay = <0>;
					};
rockchip,on-cmds160 {
							compatible = "rockchip,on-cmds";
							rockchip,cmd_type = <LPDT>;
							rockchip,dsi_id = <0>;
							rockchip,cmd = <0x15 0xAD 0x1d>;
							rockchip,cmd_delay = <0>;
					};
rockchip,on-cmds161 {
							compatible = "rockchip,on-cmds";
							rockchip,cmd_type = <LPDT>;
							rockchip,dsi_id = <0>;
							rockchip,cmd = <0x15 0xAE 0x54>;
							rockchip,cmd_delay = <0>;
					};
rockchip,on-cmds162 {
							compatible = "rockchip,on-cmds";
							rockchip,cmd_type = <LPDT>;
							rockchip,dsi_id = <0>;
							rockchip,cmd = <0x15 0xAF 0x25>;
							rockchip,cmd_delay = <0>;
					};
					rockchip,on-cmds163 {
							compatible = "rockchip,on-cmds";
							rockchip,cmd_type = <LPDT>;
							rockchip,dsi_id = <0>;
							rockchip,cmd = <0x15 0xB0 0x26>;
							rockchip,cmd_delay = <0>;
					};
					rockchip,on-cmds164 {
							compatible = "rockchip,on-cmds";
							rockchip,cmd_type = <LPDT>;
							rockchip,dsi_id = <0>;
							rockchip,cmd = <0x15 0xB1 0x4f>;
							rockchip,cmd_delay = <0>;
					};
					rockchip,on-cmds165 {
							compatible = "rockchip,on-cmds";
							rockchip,cmd_type = <LPDT>;
							rockchip,dsi_id = <0>;
							rockchip,cmd = <0x15 0xB2 0x6c>;
							rockchip,cmd_delay = <0>;
					};
					rockchip,on-cmds166 {
							compatible = "rockchip,on-cmds";
							rockchip,cmd_type = <LPDT>;
							rockchip,dsi_id = <0>;
							rockchip,cmd = <0x15 0xB3 0x39>;
							rockchip,cmd_delay = <0>;
					};
						rockchip,on-cmds167 {
							compatible = "rockchip,on-cmds";
							rockchip,cmd_type = <LPDT>;
							rockchip,dsi_id = <0>;
							rockchip,cmd = <0x15 0xC0 0x1D>;
							rockchip,cmd_delay = <0>;
					};
						rockchip,on-cmds168 {
							compatible = "rockchip,on-cmds";
							rockchip,cmd_type = <LPDT>;
							rockchip,dsi_id = <0>;
							rockchip,cmd = <0x15 0xC1 0x26>;
							rockchip,cmd_delay = <0>;
					};
						rockchip,on-cmds169 {
							compatible = "rockchip,on-cmds";
							rockchip,cmd_type = <LPDT>;
							rockchip,dsi_id = <0>;
							rockchip,cmd = <0x15 0xC2 0x31>;
							rockchip,cmd_delay = <0>;
					};
						rockchip,on-cmds170 {
							compatible = "rockchip,on-cmds";
							rockchip,cmd_type = <LPDT>;
							rockchip,dsi_id = <0>;
							rockchip,cmd = <0x15 0xC3 0x10>;
							rockchip,cmd_delay = <0>;
					};
						rockchip,on-cmds171 {
							compatible = "rockchip,on-cmds";
							rockchip,cmd_type = <LPDT>;
							rockchip,dsi_id = <0>;
							rockchip,cmd = <0x15 0xC4 0x13>;
							rockchip,cmd_delay = <0>;
					};	rockchip,on-cmds172 {
							compatible = "rockchip,on-cmds";
							rockchip,cmd_type = <LPDT>;
							rockchip,dsi_id = <0>;
							rockchip,cmd = <0x15 0xC5 0x25>;
							rockchip,cmd_delay = <0>;
					};	rockchip,on-cmds173 {
							compatible = "rockchip,on-cmds";
							rockchip,cmd_type = <LPDT>;
							rockchip,dsi_id = <0>;
							rockchip,cmd = <0x15 0xC6 0x16>;
							rockchip,cmd_delay = <0>;
					};	rockchip,on-cmds174 {
							compatible = "rockchip,on-cmds";
							rockchip,cmd_type = <LPDT>;
							rockchip,dsi_id = <0>;
							rockchip,cmd = <0x15 0xC7 0x18>;
							rockchip,cmd_delay = <0>;
					};	rockchip,on-cmds175 {
							compatible = "rockchip,on-cmds";
							rockchip,cmd_type = <LPDT>;
							rockchip,dsi_id = <0>;
							rockchip,cmd = <0x15 0xC8 0x97>;
							rockchip,cmd_delay = <0>;
					};
						rockchip,on-cmds176 {
							compatible = "rockchip,on-cmds";
							rockchip,cmd_type = <LPDT>;
							rockchip,dsi_id = <0>;
							rockchip,cmd = <0x15 0xC9 0x1f>;
							rockchip,cmd_delay = <0>;
					};
						rockchip,on-cmds177 {
							compatible = "rockchip,on-cmds";
							rockchip,cmd_type = <LPDT>;
							rockchip,dsi_id = <0>;
							rockchip,cmd = <0x15 0xCA 0x2d>;
							rockchip,cmd_delay = <0>;
					};	rockchip,on-cmds178 {
							compatible = "rockchip,on-cmds";
							rockchip,cmd_type = <LPDT>;
							rockchip,dsi_id = <0>;
							rockchip,cmd = <0x15 0xCB 0x8b>;
							rockchip,cmd_delay = <0>;
					};
						rockchip,on-cmds179 {
							compatible = "rockchip,on-cmds";
							rockchip,cmd_type = <LPDT>;
							rockchip,dsi_id = <0>;
							rockchip,cmd = <0x15 0xCC 0x21>;
							rockchip,cmd_delay = <0>;
					};
						rockchip,on-cmds180 {
							compatible = "rockchip,on-cmds";
							rockchip,cmd_type = <LPDT>;
							rockchip,dsi_id = <0>;
							rockchip,cmd = <0x15 0xCD 0x1F>;
							rockchip,cmd_delay = <0>;
					};
						rockchip,on-cmds181 {
							compatible = "rockchip,on-cmds";
							rockchip,cmd_type = <LPDT>;
							rockchip,dsi_id = <0>;
							rockchip,cmd = <0x15 0xCE 0x51>;
							rockchip,cmd_delay = <0>;
					};
						rockchip,on-cmds182 {
							compatible = "rockchip,on-cmds";
							rockchip,cmd_type = <LPDT>;
							rockchip,dsi_id = <0>;
							rockchip,cmd = <0x15 0xCF 0x27>;
							rockchip,cmd_delay = <0>;
					};
						rockchip,on-cmds183 {
							compatible = "rockchip,on-cmds";
							rockchip,cmd_type = <LPDT>;
							rockchip,dsi_id = <0>;
							rockchip,cmd = <0x15 0xD0 0x2c>;
							rockchip,cmd_delay = <0>;
					};
					rockchip,on-cmds184 {
							compatible = "rockchip,on-cmds";
							rockchip,cmd_type = <LPDT>;
							rockchip,dsi_id = <0>;
							rockchip,cmd = <0x15 0xD1 0x53>;
							rockchip,cmd_delay = <0>;
					};
					rockchip,on-cmds185 {
							compatible = "rockchip,on-cmds";
							rockchip,cmd_type = <LPDT>;
							rockchip,dsi_id = <0>;
							rockchip,cmd = <0x15 0xD2 0x70>;
							rockchip,cmd_delay = <0>;
					};
					rockchip,on-cmds186 {
							compatible = "rockchip,on-cmds";
							rockchip,cmd_type = <LPDT>;
							rockchip,dsi_id = <0>;
							rockchip,cmd = <0x15 0xD3 0x39>;
							rockchip,cmd_delay = <0>;
					};
					rockchip,on-cmds187 {
							compatible = "rockchip,on-cmds";
							rockchip,cmd_type = <LPDT>;
							rockchip,dsi_id = <0>;
							rockchip,cmd = <0x39 0xFF 0x98 0x81 0x00>;//cmd page0
							rockchip,cmd_delay = <0>;
					};
					rockchip,on-cmds188 {
							compatible = "rockchip,on-cmds";
							rockchip,cmd_type = <LPDT>;
							rockchip,dsi_id = <0>;
							rockchip,cmd = <0x15 0x11 0x00>;
							rockchip,cmd_delay = <200>;
					};
					rockchip,on-cmds189 {
							compatible = "rockchip,on-cmds";
							rockchip,cmd_type = <LPDT>;
							rockchip,dsi_id = <0>;
							rockchip,cmd = <0x15 0x29 0x00>;
							rockchip,cmd_delay = <20>;
					};
					rockchip,on-cmds190 {
							compatible = "rockchip,on-cmds";
							rockchip,cmd_type = <LPDT>;
							rockchip,dsi_id = <0>;
							rockchip,cmd = <0x15 0x35 0x00>;
							rockchip,cmd_delay = <10>;
					};		
		};
		
		disp_timings: display-timings {
                        native-mode = <&timing0>;
                        compatible = "rockchip,display-timings";
                        timing0: timing0 {
				screen-type = <SCREEN_MIPI>;
				//lvds-format = <LVDS_8BIT_2>;
				out-face    = <OUT_P888>;
				clock-frequency = <65000000>;//has color;20170321-3,can but not good;
				//clock-frequency = <80000000>;//no;20170321-2,no;
//				//clock-frequency = <75000000>;//has color;can but not good;20170321-1,can but not good;
				//clock-frequency = <82500000>;
				//clock-frequency = <50000000>;
				//clock-frequency = <33000000>;
				//clock-frequency = <70000000>;//has color;can but not good;
				//clock-frequency = <65000000>;//no
				hactive = <720>;//720
				vactive = <1280>;
				hsync-len = <2>;//2
				hback-porch = <36>;//16
				hfront-porch = <4>;

				vsync-len = <3>;//4
				vback-porch = <20>;
				vfront-porch = <16>;

				hsync-active = <0>;
				vsync-active = <0>;
				de-active = <0>;
				pixelclk-active = <0>;
				swap-rb = <0>;
				swap-rg = <0>;
				swap-gb = <0>;
                     	};


               };
};
